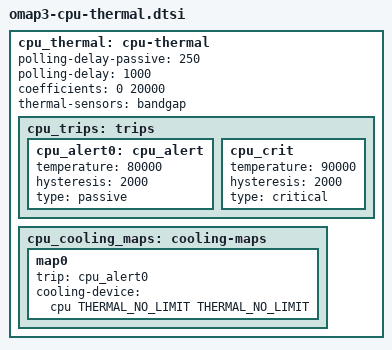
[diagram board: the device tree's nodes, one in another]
#include <dt-bindings/thermal/thermal.h>
cpu_thermal: cpu-thermal {
	polling-delay-passive = <250>;  
	polling-delay = <1000>;  
	coefficients = <0 20000>;
	thermal-sensors = <&bandgap>;
	cpu_trips: trips {
		cpu_alert0: cpu_alert {
			temperature = <80000>;  
			hysteresis = <2000>;  
			type = "passive";
		};
		cpu_crit: cpu_crit {
			temperature = <90000>;  
			hysteresis = <2000>;  
			type = "critical";
		};
	};
	cpu_cooling_maps: cooling-maps {
		map0 {
			trip = <&cpu_alert0>;
			cooling-device =
				<&cpu THERMAL_NO_LIMIT THERMAL_NO_LIMIT>;
		};
	};
};
